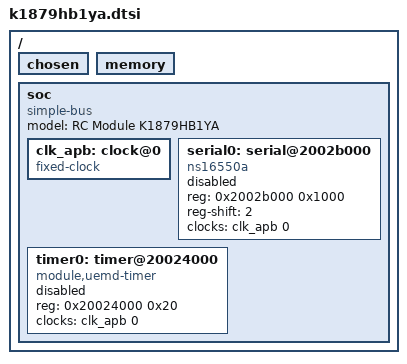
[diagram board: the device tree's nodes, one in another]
/ {
	#address-cells = <1>;
	#size-cells = <1>;

	chosen { };

	memory {
		device_type = "memory";
	};

	soc {
		compatible = "simple-bus";
		model = "RC Module K1879HB1YA";
		#address-cells = <1>;
		#size-cells = <1>;
		ranges;

		/*
		 * Actually clk_apb is not a fixed-clock at all.
		 * clk_apb is a derivated clock, but for the moment
		 * there is no public documentation on k1879hb1ya
		 * so we can't describe it correctly.
		 */
		clk_apb: clock@0 {
			compatible = "fixed-clock";
			#clock-cells = <0>;
		};

		serial0: serial@2002b000 {
			compatible = "ns16550a";
			reg = <0x2002b000 0x1000>;
			reg-shift = <2>;
			clocks = <&clk_apb 0>;
			status = "disabled";
		};

		timer0: timer@20024000 {
			compatible = "module,uemd-timer";
			reg = <0x20024000 0x20>;
			clocks = <&clk_apb 0>;
			status = "disabled";
		};
	};
};
